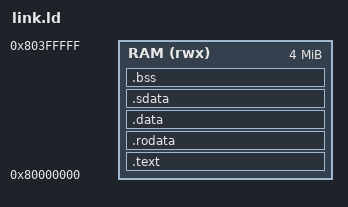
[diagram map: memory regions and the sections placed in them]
/* Linker script for bare-metal programs on rv_soc (4 MiB RAM @ 0x80000000). */
OUTPUT_ARCH("riscv")
ENTRY(_start)

MEMORY
{
    RAM (rwx) : ORIGIN = 0x80000000, LENGTH = 4M
}

SECTIONS
{
    .text : {
        KEEP(*(.text.init))
        *(.text .text.*)
    } > RAM

    .rodata : ALIGN(4) {
        *(.rodata .rodata.*)
        *(.srodata .srodata.*)
    } > RAM

    .data : ALIGN(4) {
        *(.data .data.*)
    } > RAM

    .sdata : ALIGN(4) {
        __global_pointer$ = . + 0x800;
        *(.sdata .sdata.*)
    } > RAM

    .bss (NOLOAD) : ALIGN(4) {
        __bss_start = .;
        *(.sbss .sbss.*)
        *(.bss .bss.*)
        *(COMMON)
        . = ALIGN(4);
        __bss_end = .;
    } > RAM

    . = ALIGN(16);
    _end = .;
    __heap_start = .;
    __stack_top = ORIGIN(RAM) + LENGTH(RAM);
}
